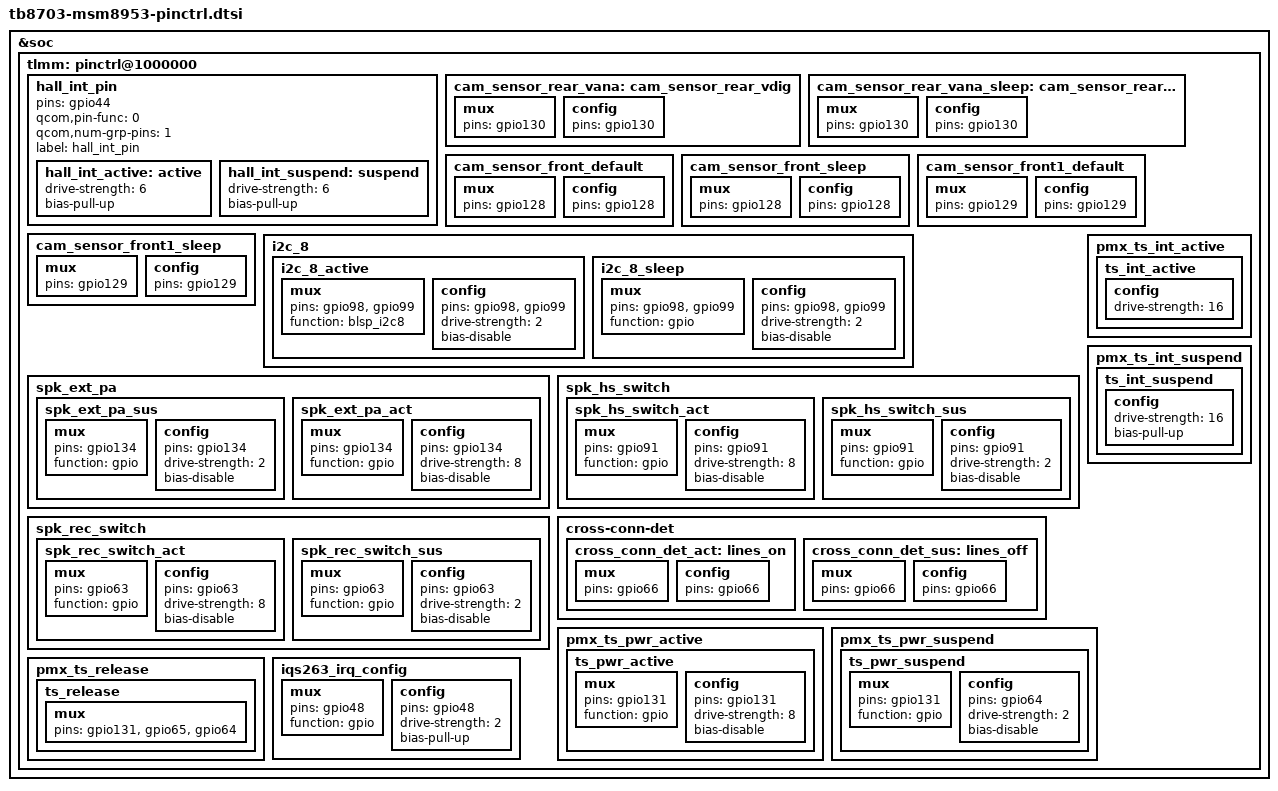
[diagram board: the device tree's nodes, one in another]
/*
 * Copyright (c) 2015-2016, The Linux Foundation. All rights reserved.
 *
 * This program is free software; you can redistribute it and/or modify
 * it under the terms of the GNU General Public License version 2 and
 * only version 2 as published by the Free Software Foundation.
 *
 * This program is distributed in the hope that it will be useful,
 * but WITHOUT ANY WARRANTY; without even the implied warranty of
 * MERCHANTABILITY or FITNESS FOR A PARTICULAR PURPOSE.  See the
 * GNU General Public License for more details.
 */

&soc {
	tlmm: pinctrl@1000000 {
		hall_int_pin {
			//qcom,pins = <&gp 13>;
			pins = "gpio44";
			qcom,pin-func = <0>;
			qcom,num-grp-pins = <1>;
			label = "hall_int_pin";
			hall_int_active: active {
				drive-strength = <6>;
				bias-pull-up;
			};
			hall_int_suspend: suspend {
				drive-strength = <6>;
				bias-pull-up;
			};
		};

		cam_sensor_rear_vana: cam_sensor_rear_vdig {
			/* VDIG */
			mux {
				pins = "gpio130";
			};

			config {
				pins = "gpio130";
			};
		};

		cam_sensor_rear_vana_sleep: cam_sensor_rear_vdig_sleep {
			/* VDIG */
			mux {
				pins = "gpio130";
			};

			config {
				pins = "gpio130";
			};
		};


		cam_sensor_front_default: cam_sensor_front_default {
			/* RESET, STANDBY */
			mux {
				pins = "gpio128";
			};

			config {
				pins = "gpio128";
			};
		};

		cam_sensor_front_sleep: cam_sensor_front_sleep {
			/* RESET, STANDBY */
			mux {
				pins = "gpio128";
			};

			config {
				pins = "gpio128";
			};
		};


		cam_sensor_front1_default: cam_sensor_front1_default {
			/* RESET, STANDBY */
			mux {
				pins = "gpio129";
			};

			config {
				pins = "gpio129";
			};
		};

		cam_sensor_front1_sleep: cam_sensor_front1_sleep {
			/* RESET, STANDBY */
			mux {
				pins = "gpio129";
			};

			config {
				pins = "gpio129";
			};
		};

		i2c_8 {
			i2c_8_active: i2c_8_active {
				/* active state */
				mux {
					pins = "gpio98", "gpio99";
					function = "blsp_i2c8";
				};

				config {
					pins = "gpio98", "gpio99";
					drive-strength = <2>;
					bias-disable;
				};
			};

			i2c_8_sleep: i2c_8_sleep {
				/* suspended state */
				mux {
					pins = "gpio98", "gpio99";
					function = "gpio";
				};

				config {
					pins = "gpio98", "gpio99";
					drive-strength = <2>;
					bias-disable;
				};
			};
		};

		spk_ext_pa {
			spk_ext_pa_sus: spk_ext_pa_sus {
				mux {
					pins = "gpio134";
					function = "gpio";
				};
				config {
				    pins = "gpio134";
				    drive-strength = <2>;
				    //output-low;
				    //bias-pull-down;
				    bias-disable;
				};
			};
			spk_ext_pa_act: spk_ext_pa_act {
				mux {
					pins = "gpio134";
					function = "gpio";
				};
				config {
				    pins = "gpio134";
				    drive-strength = <8>;
				    bias-disable;
				};
			};
		};

		spk_hs_switch {
			spk_hs_switch_act: spk_hs_switch_act {
				mux {
					pins = "gpio91";
					function = "gpio";
				};
				config {
				    pins = "gpio91";
				    drive-strength = <8>;
				    bias-disable;
				    //output-high;
				};
			};
			spk_hs_switch_sus: spk_hs_switch_sus {
				mux {
					pins = "gpio91";
					function = "gpio";
				};
				config {
					pins = "gpio91";
					drive-strength = <2>;
					bias-disable;
				};
			};
		};
		
		spk_rec_switch {
			spk_rec_switch_act: spk_rec_switch_act {
				mux {
					pins = "gpio63";
					function = "gpio";
				};
				config {
			        pins = "gpio63";
					drive-strength = <8>;
					bias-disable;
					//output-high;
				};
			};
			spk_rec_switch_sus: spk_rec_switch_sus {
				mux {
					pins = "gpio63";
					function = "gpio";
				};
				config {
					pins = "gpio63";
					drive-strength = <2>;
					bias-disable;
				};
			};
		};

		cross-conn-det {
			cross_conn_det_act: lines_on {
				mux {
					pins = "gpio66";
				};

				config {
					pins = "gpio66";
				};
			};

			cross_conn_det_sus: lines_off {
				mux {
					pins = "gpio66";
				};

				config {
					pins = "gpio66";
				};
			};
		};


		/* add pingrp for touchscreen */
		pmx_ts_int_active {
			ts_int_active: ts_int_active {

				config {
					drive-strength = <16>;
				};
			};
		};

		pmx_ts_int_suspend {
			ts_int_suspend: ts_int_suspend {

				config {
					drive-strength = <16>;
					bias-pull-up;
				};
			};
		};

		pmx_ts_pwr_active {
			ts_pwr_active: ts_pwr_active {
				mux {
					pins = "gpio131";
					function = "gpio";
				};

				config {
					pins = "gpio131";
					drive-strength = <8>;
					bias-disable;
				};
			};
		};

		pmx_ts_pwr_suspend {
			ts_pwr_suspend: ts_pwr_suspend {
				mux {
					pins = "gpio131";
					function = "gpio";
				};

				config {
					pins = "gpio64";
					drive-strength = <2>;
					bias-disable;
				};
			};
		};

		pmx_ts_release {
			ts_release: ts_release {
				mux {
					pins = "gpio131", "gpio65", "gpio64";
				};
			};
		};

		iqs263_irq_config: iqs263_irq_config {
			mux {
				pins = "gpio48";
				function = "gpio";
			};

			config {
				pins = "gpio48";
				drive-strength = <2>;
				bias-pull-up;
			};
		};
	};
};
